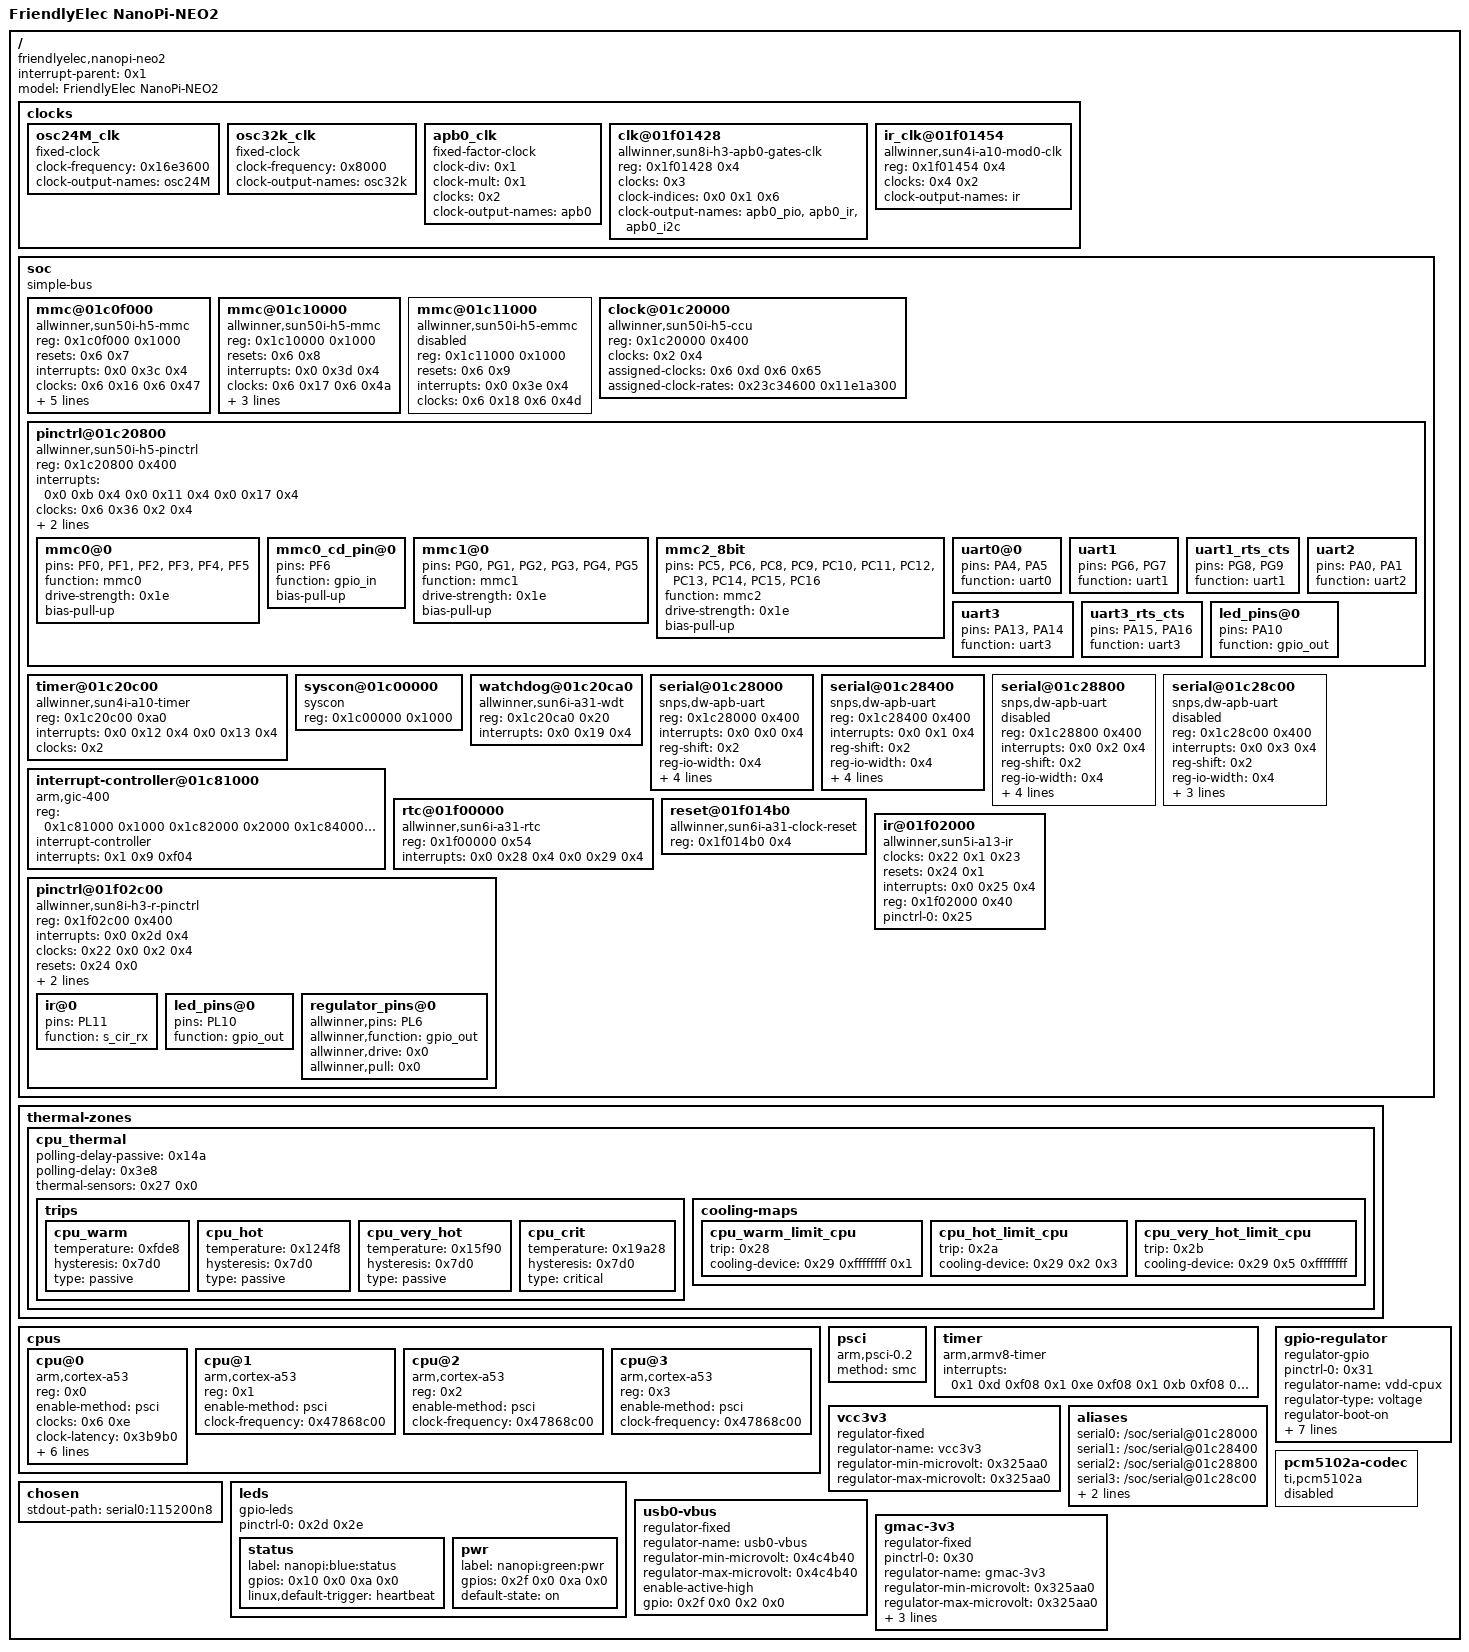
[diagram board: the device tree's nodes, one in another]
/dts-v1/;

/ {
	interrupt-parent = <0x1>;
	#address-cells = <0x1>;
	#size-cells = <0x1>;
	model = "FriendlyElec NanoPi-NEO2";
	compatible = "friendlyelec,nanopi-neo2", "allwinner,sun50i-h5";

	clocks {
		#address-cells = <0x1>;
		#size-cells = <0x1>;
		ranges;

		osc24M_clk {
			#clock-cells = <0x0>;
			compatible = "fixed-clock";
			clock-frequency = <0x16e3600>;
			clock-output-names = "osc24M";
			linux,phandle = <0x2>;
			phandle = <0x2>;
		};

		osc32k_clk {
			#clock-cells = <0x0>;
			compatible = "fixed-clock";
			clock-frequency = <0x8000>;
			clock-output-names = "osc32k";
			linux,phandle = <0x4>;
			phandle = <0x4>;
		};

		apb0_clk {
			compatible = "fixed-factor-clock";
			#clock-cells = <0x0>;
			clock-div = <0x1>;
			clock-mult = <0x1>;
			clocks = <0x2>;
			clock-output-names = "apb0";
			linux,phandle = <0x3>;
			phandle = <0x3>;
		};

		clk@01f01428 {
			compatible = "allwinner,sun8i-h3-apb0-gates-clk", "allwinner,sun4i-a10-gates-clk";
			reg = <0x1f01428 0x4>;
			#clock-cells = <0x1>;
			clocks = <0x3>;
			clock-indices = <0x0 0x1 0x6>;
			clock-output-names = "apb0_pio", "apb0_ir", "apb0_i2c";
			linux,phandle = <0x22>;
			phandle = <0x22>;
		};

		ir_clk@01f01454 {
			compatible = "allwinner,sun4i-a10-mod0-clk";
			reg = <0x1f01454 0x4>;
			#clock-cells = <0x0>;
			clocks = <0x4 0x2>;
			clock-output-names = "ir";
			linux,phandle = <0x23>;
			phandle = <0x23>;
		};
	};

	soc {
		compatible = "simple-bus";
		#address-cells = <0x1>;
		#size-cells = <0x1>;
		ranges;

		mmc@01c0f000 {
			reg = <0x1c0f000 0x1000>;
			resets = <0x6 0x7>;
			reset-names = "ahb";
			interrupts = <0x0 0x3c 0x4>;
			status = "okay";
			#address-cells = <0x1>;
			#size-cells = <0x0>;
			compatible = "allwinner,sun50i-h5-mmc", "allwinner,sun50i-a64-mmc";
			clocks = <0x6 0x16 0x6 0x47>;
			clock-names = "ahb", "mmc";
			pinctrl-names = "default";
			pinctrl-0 = <0xd 0xe>;
			vmmc-supply = <0xf>;
			bus-width = <0x4>;
			cd-gpios = <0x10 0x5 0x6 0x1>;
			boot_device = <0x1>;
		};

		mmc@01c10000 {
			reg = <0x1c10000 0x1000>;
			resets = <0x6 0x8>;
			reset-names = "ahb";
			interrupts = <0x0 0x3d 0x4>;
			status = "okay";
			#address-cells = <0x1>;
			#size-cells = <0x0>;
			compatible = "allwinner,sun50i-h5-mmc", "allwinner,sun50i-a64-mmc";
			clocks = <0x6 0x17 0x6 0x4a>;
			clock-names = "ahb", "mmc";
			pinctrl-names = "default";
			pinctrl-0 = <0x11>;
			vmmc-supply = <0xf>;
			bus-width = <0x4>;
		};

		mmc@01c11000 {
			reg = <0x1c11000 0x1000>;
			resets = <0x6 0x9>;
			reset-names = "ahb";
			interrupts = <0x0 0x3e 0x4>;
			status = "disabled";
			#address-cells = <0x1>;
			#size-cells = <0x0>;
			compatible = "allwinner,sun50i-h5-emmc", "allwinner,sun50i-a64-emmc";
			clocks = <0x6 0x18 0x6 0x4d>;
			clock-names = "ahb", "mmc";
		};

		clock@01c20000 {
			reg = <0x1c20000 0x400>;
			clocks = <0x2 0x4>;
			clock-names = "hosc", "losc";
			#clock-cells = <0x1>;
			#reset-cells = <0x1>;
			assigned-clocks = <0x6 0xd 0x6 0x65>;
			assigned-clock-rates = <0x23c34600 0x11e1a300>;
			compatible = "allwinner,sun50i-h5-ccu";
			linux,phandle = <0x6>;
			phandle = <0x6>;
		};

		pinctrl@01c20800 {
			reg = <0x1c20800 0x400>;
			interrupts = <0x0 0xb 0x4 0x0 0x11 0x4 0x0 0x17 0x4>;
			clocks = <0x6 0x36 0x2 0x4>;
			clock-names = "apb", "hosc", "losc";
			gpio-controller;
			#gpio-cells = <0x3>;
			interrupt-controller;
			#interrupt-cells = <0x3>;
			compatible = "allwinner,sun50i-h5-pinctrl";
			linux,phandle = <0x10>;
			phandle = <0x10>;

			mmc0@0 {
				pins = "PF0", "PF1", "PF2", "PF3", "PF4", "PF5";
				function = "mmc0";
				drive-strength = <0x1e>;
				bias-pull-up;
				linux,phandle = <0xd>;
				phandle = <0xd>;
			};

			mmc0_cd_pin@0 {
				pins = "PF6";
				function = "gpio_in";
				bias-pull-up;
				linux,phandle = <0xe>;
				phandle = <0xe>;
			};

			mmc1@0 {
				pins = "PG0", "PG1", "PG2", "PG3", "PG4", "PG5";
				function = "mmc1";
				drive-strength = <0x1e>;
				bias-pull-up;
				linux,phandle = <0x11>;
				phandle = <0x11>;
			};

			mmc2_8bit {
				pins = "PC5", "PC6", "PC8", "PC9", "PC10", "PC11", "PC12", "PC13", "PC14", "PC15", "PC16";
				function = "mmc2";
				drive-strength = <0x1e>;
				bias-pull-up;
			};

			uart0@0 {
				pins = "PA4", "PA5";
				function = "uart0";
				linux,phandle = <0x1c>;
				phandle = <0x1c>;
			};

			uart1 {
				pins = "PG6", "PG7";
				function = "uart1";
				linux,phandle = <0x1d>;
				phandle = <0x1d>;
			};

			uart1_rts_cts {
				pins = "PG8", "PG9";
				function = "uart1";
			};

			uart2 {
				pins = "PA0", "PA1";
				function = "uart2";
				linux,phandle = <0x1e>;
				phandle = <0x1e>;
			};

			uart3 {
				pins = "PA13", "PA14";
				function = "uart3";
			};

			uart3_rts_cts {
				pins = "PA15", "PA16";
				function = "uart3";
			};

			led_pins@0 {
				pins = "PA10";
				function = "gpio_out";
				linux,phandle = <0x2d>;
				phandle = <0x2d>;
			};
		};

		timer@01c20c00 {
			compatible = "allwinner,sun4i-a10-timer";
			reg = <0x1c20c00 0xa0>;
			interrupts = <0x0 0x12 0x4 0x0 0x13 0x4>;
			clocks = <0x2>;
		};

		syscon@01c00000 {
			compatible = "syscon", "allwinner,sun8i-h3-system-controller";
			reg = <0x1c00000 0x1000>;
			linux,phandle = <0x5>;
			phandle = <0x5>;
		};

		watchdog@01c20ca0 {
			compatible = "allwinner,sun6i-a31-wdt";
			reg = <0x1c20ca0 0x20>;
			interrupts = <0x0 0x19 0x4>;
		};

		serial@01c28000 {
			compatible = "snps,dw-apb-uart";
			reg = <0x1c28000 0x400>;
			interrupts = <0x0 0x0 0x4>;
			reg-shift = <0x2>;
			reg-io-width = <0x4>;
			clocks = <0x6 0x3e>;
			resets = <0x6 0x31>;
			dmas = <0x14 0x6 0x14 0x6>;
			dma-names = "rx", "tx";
			status = "okay";
			pinctrl-names = "default";
			pinctrl-0 = <0x1c>;
		};

		serial@01c28400 {
			compatible = "snps,dw-apb-uart";
			reg = <0x1c28400 0x400>;
			interrupts = <0x0 0x1 0x4>;
			reg-shift = <0x2>;
			reg-io-width = <0x4>;
			clocks = <0x6 0x3f>;
			resets = <0x6 0x32>;
			dmas = <0x14 0x7 0x14 0x7>;
			dma-names = "rx", "tx";
			status = "okay";
			pinctrl-names = "default";
			pinctrl-0 = <0x1d>;
		};

		serial@01c28800 {
			compatible = "snps,dw-apb-uart";
			reg = <0x1c28800 0x400>;
			interrupts = <0x0 0x2 0x4>;
			reg-shift = <0x2>;
			reg-io-width = <0x4>;
			clocks = <0x6 0x40>;
			resets = <0x6 0x33>;
			dmas = <0x14 0x8 0x14 0x8>;
			dma-names = "rx", "tx";
			status = "disabled";
			pinctrl-names = "default";
			pinctrl-0 = <0x1e>;
		};

		serial@01c28c00 {
			compatible = "snps,dw-apb-uart";
			reg = <0x1c28c00 0x400>;
			interrupts = <0x0 0x3 0x4>;
			reg-shift = <0x2>;
			reg-io-width = <0x4>;
			clocks = <0x6 0x41>;
			resets = <0x6 0x34>;
			dmas = <0x14 0x9 0x14 0x9>;
			dma-names = "rx", "tx";
			status = "disabled";
		};

		interrupt-controller@01c81000 {
			compatible = "arm,gic-400";
			reg = <0x1c81000 0x1000 0x1c82000 0x2000 0x1c84000 0x2000 0x1c86000 0x2000>;
			interrupt-controller;
			#interrupt-cells = <0x3>;
			interrupts = <0x1 0x9 0xf04>;
			linux,phandle = <0x1>;
			phandle = <0x1>;
		};

		rtc@01f00000 {
			compatible = "allwinner,sun6i-a31-rtc";
			reg = <0x1f00000 0x54>;
			interrupts = <0x0 0x28 0x4 0x0 0x29 0x4>;
		};

		reset@01f014b0 {
			reg = <0x1f014b0 0x4>;
			compatible = "allwinner,sun6i-a31-clock-reset";
			#reset-cells = <0x1>;
			linux,phandle = <0x24>;
			phandle = <0x24>;
		};

		ir@01f02000 {
			compatible = "allwinner,sun5i-a13-ir";
			clocks = <0x22 0x1 0x23>;
			clock-names = "apb", "ir";
			resets = <0x24 0x1>;
			interrupts = <0x0 0x25 0x4>;
			reg = <0x1f02000 0x40>;
			status = "okay";
			pinctrl-names = "default";
			pinctrl-0 = <0x25>;
		};

		pinctrl@01f02c00 {
			compatible = "allwinner,sun8i-h3-r-pinctrl";
			reg = <0x1f02c00 0x400>;
			interrupts = <0x0 0x2d 0x4>;
			clocks = <0x22 0x0 0x2 0x4>;
			clock-names = "apb", "hosc", "losc";
			resets = <0x24 0x0>;
			gpio-controller;
			#gpio-cells = <0x3>;
			interrupt-controller;
			#interrupt-cells = <0x3>;
			linux,phandle = <0x2f>;
			phandle = <0x2f>;

			ir@0 {
				pins = "PL11";
				function = "s_cir_rx";
				linux,phandle = <0x25>;
				phandle = <0x25>;
			};

			led_pins@0 {
				pins = "PL10";
				function = "gpio_out";
				linux,phandle = <0x2e>;
				phandle = <0x2e>;
			};

			regulator_pins@0 {
				allwinner,pins = "PL6";
				allwinner,function = "gpio_out";
				allwinner,drive = <0x0>;
				allwinner,pull = <0x0>;
				linux,phandle = <0x31>;
				phandle = <0x31>;
			};
		};
	};

	thermal-zones {

		cpu_thermal {
			polling-delay-passive = <0x14a>;
			polling-delay = <0x3e8>;
			thermal-sensors = <0x27 0x0>;

			trips {

				cpu_warm {
					temperature = <0xfde8>;
					hysteresis = <0x7d0>;
					type = "passive";
					linux,phandle = <0x28>;
					phandle = <0x28>;
				};

				cpu_hot {
					temperature = <0x124f8>;
					hysteresis = <0x7d0>;
					type = "passive";
					linux,phandle = <0x2a>;
					phandle = <0x2a>;
				};

				cpu_very_hot {
					temperature = <0x15f90>;
					hysteresis = <0x7d0>;
					type = "passive";
					linux,phandle = <0x2b>;
					phandle = <0x2b>;
				};

				cpu_crit {
					temperature = <0x19a28>;
					hysteresis = <0x7d0>;
					type = "critical";
				};
			};

			cooling-maps {

				cpu_warm_limit_cpu {
					trip = <0x28>;
					cooling-device = <0x29 0xffffffff 0x1>;
				};

				cpu_hot_limit_cpu {
					trip = <0x2a>;
					cooling-device = <0x29 0x2 0x3>;
				};

				cpu_very_hot_limit_cpu {
					trip = <0x2b>;
					cooling-device = <0x29 0x5 0xffffffff>;
				};
			};
		};
	};

	cpus {
		#address-cells = <0x1>;
		#size-cells = <0x0>;

		cpu@0 {
			compatible = "arm,cortex-a53", "arm,armv8";
			device_type = "cpu";
			reg = <0x0>;
			enable-method = "psci";
			clocks = <0x6 0xe>;
			clock-latency = <0x3b9b0>;
			clock-frequency = <0x47868c00>;
			operating-points = <0xf6180 0x10c8e0 0xc7380 0x10c8e0 0x98580 0x10c8e0 0x75300 0x10c8e0 0x4c2c0 0x10c8e0 0x3a980 0x10c8e0 0x1d4c0 0x10c8e0>;
			#cooling-cells = <0x2>;
			cooling-min-level = <0x0>;
			cooling-max-level = <0x6>;
			cpu0-supply = <0x2c>;
			linux,phandle = <0x29>;
			phandle = <0x29>;
		};

		cpu@1 {
			compatible = "arm,cortex-a53", "arm,armv8";
			device_type = "cpu";
			reg = <0x1>;
			enable-method = "psci";
			clock-frequency = <0x47868c00>;
		};

		cpu@2 {
			compatible = "arm,cortex-a53", "arm,armv8";
			device_type = "cpu";
			reg = <0x2>;
			enable-method = "psci";
			clock-frequency = <0x47868c00>;
		};

		cpu@3 {
			compatible = "arm,cortex-a53", "arm,armv8";
			device_type = "cpu";
			reg = <0x3>;
			enable-method = "psci";
			clock-frequency = <0x47868c00>;
		};
	};

	psci {
		compatible = "arm,psci-0.2";
		method = "smc";
	};

	timer {
		compatible = "arm,armv8-timer";
		interrupts = <0x1 0xd 0xf08 0x1 0xe 0xf08 0x1 0xb 0xf08 0x1 0xa 0xf08>;
	};

	vcc3v3 {
		compatible = "regulator-fixed";
		regulator-name = "vcc3v3";
		regulator-min-microvolt = <0x325aa0>;
		regulator-max-microvolt = <0x325aa0>;
		linux,phandle = <0xf>;
		phandle = <0xf>;
	};

	aliases {
		serial0 = "/soc/serial@01c28000";
		serial1 = "/soc/serial@01c28400";
		serial2 = "/soc/serial@01c28800";
		serial3 = "/soc/serial@01c28c00";

		mmc0 = "/soc/mmc@01c0f000";
		mmc2 = "/soc/mmc@01c11000";
	};

	chosen {
		stdout-path = "serial0:115200n8";
	};

	leds {
		compatible = "gpio-leds";
		pinctrl-names = "default";
		pinctrl-0 = <0x2d 0x2e>;

		status {
			label = "nanopi:blue:status";
			gpios = <0x10 0x0 0xa 0x0>;
			linux,default-trigger = "heartbeat";
		};

		pwr {
			label = "nanopi:green:pwr";
			gpios = <0x2f 0x0 0xa 0x0>;
			default-state = "on";
		};
	};

	usb0-vbus {
		compatible = "regulator-fixed";
		regulator-name = "usb0-vbus";
		regulator-min-microvolt = <0x4c4b40>;
		regulator-max-microvolt = <0x4c4b40>;
		enable-active-high;
		gpio = <0x2f 0x0 0x2 0x0>;
		status = "okay";
		linux,phandle = <0x13>;
		phandle = <0x13>;
	};

	gmac-3v3 {
		compatible = "regulator-fixed";
		pinctrl-names = "default";
		pinctrl-0 = <0x30>;
		regulator-name = "gmac-3v3";
		regulator-min-microvolt = <0x325aa0>;
		regulator-max-microvolt = <0x325aa0>;
		startup-delay-us = <0x186a0>;
		enable-active-high;
		gpio = <0x10 0x3 0x6 0x0>;
		linux,phandle = <0x8>;
		phandle = <0x8>;
	};

	gpio-regulator {
		compatible = "regulator-gpio";
		pinctrl-names = "default";
		pinctrl-0 = <0x31>;
		regulator-name = "vdd-cpux";
		regulator-type = "voltage";
		regulator-boot-on;
		regulator-always-on;
		regulator-min-microvolt = <0x10c8e0>;
		regulator-max-microvolt = <0x10c8e0>;
		regulator-ramp-delay = <0x32>;
		gpios = <0x2f 0x0 0x6 0x0>;
		gpios-states = <0x1>;
		states = <0x10c8e0 0x0 0x10c8e0 0x1>;
		linux,phandle = <0x2c>;
		phandle = <0x2c>;
	};

	pcm5102a-codec {
		#sound-dai-cells = <0x0>;
		compatible = "ti,pcm5102a";
		status = "disabled";
		linux,phandle = <0x1b>;
		phandle = <0x1b>;
	};
};
